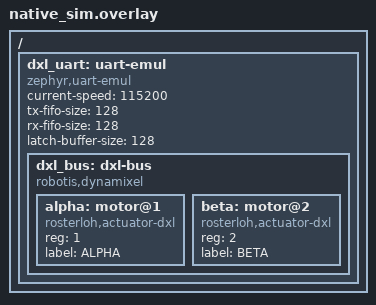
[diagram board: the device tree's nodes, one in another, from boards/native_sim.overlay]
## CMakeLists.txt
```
cmake_minimum_required(VERSION 3.20.0)
find_package(Zephyr REQUIRED HINTS $ENV{ZEPHYR_BASE})
project(actuator_group_dxl)
target_sources(app PRIVATE src/main.c)
```

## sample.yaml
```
sample:
  name: Actuator group_dxl demo
  description: Multi-Dynamixel group with SYNC_WRITE/SYNC_READ via the actuator API.
tests:
  sample.actuator.group_dxl:
    tags: actuator
    platform_allow: native_sim
    build_only: true
```

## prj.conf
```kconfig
CONFIG_LOG=y
CONFIG_LOG_DEFAULT_LEVEL=3
CONFIG_ACTUATOR=y
CONFIG_ACTUATOR_DXL=y
CONFIG_DYNAMIXEL=y
CONFIG_FPU=y
CONFIG_SERIAL=y
CONFIG_UART_INTERRUPT_DRIVEN=y
CONFIG_EMUL=y
CONFIG_UART_EMUL=y
```

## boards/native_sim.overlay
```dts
/*
 * Copyright (c) 2026 Richard Osterloh <richard.osterloh@gmail.com>
 * SPDX-License-Identifier: Apache-2.0
 */

/ {
	dxl_uart: uart-emul {
		compatible = "zephyr,uart-emul";
		current-speed = <115200>;
		tx-fifo-size = <128>;
		rx-fifo-size = <128>;
		latch-buffer-size = <128>;
		status = "okay";

		dxl_bus: dxl-bus {
			compatible = "robotis,dynamixel";
			#address-cells = <1>;
			#size-cells = <0>;
			status = "okay";

			alpha: motor@1 {
				compatible = "rosterloh,actuator-dxl";
				reg = <1>;
				label = "ALPHA";
			};

			beta: motor@2 {
				compatible = "rosterloh,actuator-dxl";
				reg = <2>;
				label = "BETA";
			};
		};
	};
};
```

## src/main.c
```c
/*
 * Copyright (c) 2026 Richard Osterloh <richard.osterloh@gmail.com>
 * SPDX-License-Identifier: Apache-2.0
 */

#include <math.h>
#include <zephyr/kernel.h>
#include <zephyr/logging/log.h>
#include <zephyr/actuator/actuator.h>
#include <zephyr/actuator/actuator_group.h>

LOG_MODULE_REGISTER(actuator_group, LOG_LEVEL_INF);

#define ALPHA DEVICE_DT_GET(DT_NODELABEL(alpha))
#define BETA  DEVICE_DT_GET(DT_NODELABEL(beta))

ACTUATOR_GROUP_DEFINE(arm, ALPHA, BETA);

static void on_state(const struct device *dev, enum actuator_state s, void *ud)
{
	ARG_UNUSED(ud);
	LOG_INF("%s -> state %d", dev->name, s);
}

int main(void)
{
	(void)actuator_register_state_cb(ALPHA, on_state, NULL);
	(void)actuator_register_state_cb(BETA, on_state, NULL);

	(void)actuator_group_set_fault_policy(&arm, ACTUATOR_GROUP_POLICY_DISABLE_ALL);
	(void)actuator_group_enable(&arm);

	float t = 0.0f;
	while (1) {
		float goals[] = {sinf(t), -sinf(t)};
		(void)actuator_group_set_position(&arm, goals);

		struct actuator_feedback fb[2];
		if (actuator_group_read_feedback(&arm, fb) == 0) {
			LOG_INF("alpha=%.3f beta=%.3f", (double)fb[0].position,
				(double)fb[1].position);
		}
		t += 0.1f;
		k_sleep(K_MSEC(50));
	}
	return 0;
}
```
